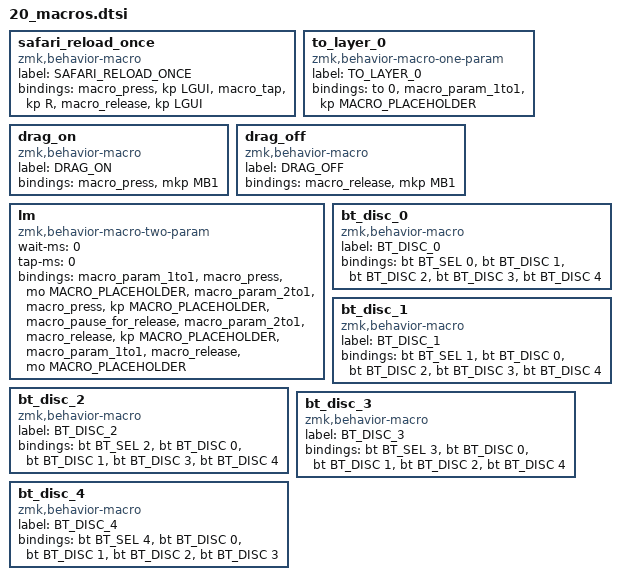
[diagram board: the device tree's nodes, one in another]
/* ============================================================
 * 20_macros.dtsi — マクロ定義
 *
 * macros { } の内側でインクルードされる。
 * ============================================================ */

safari_reload_once: safari_reload_once {
    compatible = "zmk,behavior-macro";
    label = "SAFARI_RELOAD_ONCE";
    #binding-cells = <0>;
    bindings =
        <&macro_press>,
        <&kp LGUI>,
        <&macro_tap>,
        <&kp R>,
        <&macro_release>,
        <&kp LGUI>;
};

to_layer_0: to_layer_0 {
    compatible = "zmk,behavior-macro-one-param";
    label = "TO_LAYER_0";
    #binding-cells = <1>;
    bindings = <&to 0 &macro_param_1to1 &kp MACRO_PLACEHOLDER>;
};

drag_on: drag_on {
    compatible = "zmk,behavior-macro";
    label = "DRAG_ON";
    #binding-cells = <0>;
    bindings = <&macro_press>, <&mkp MB1>;
};

drag_off: drag_off {
    compatible = "zmk,behavior-macro";
    label = "DRAG_OFF";
    #binding-cells = <0>;
    bindings = <&macro_release>, <&mkp MB1>;
};

lm: lm {
    compatible = "zmk,behavior-macro-two-param";
    #binding-cells = <2>;
    wait-ms = <0>;
    tap-ms = <0>;
    bindings =
        <&macro_param_1to1>,
        <&macro_press>,
        <&mo MACRO_PLACEHOLDER &macro_param_2to1>,
        <&macro_press>,
        <&kp MACRO_PLACEHOLDER>,
        <&macro_pause_for_release>,
        <&macro_param_2to1>,
        <&macro_release>,
        <&kp MACRO_PLACEHOLDER &macro_param_1to1>,
        <&macro_release>,
        <&mo MACRO_PLACEHOLDER>;
};

/* ============================================================
 * 〈BT Disc Sigils〉— 複数接続切断 + プロファイル切替
 *
 * bt_disc_N: BT_SEL N で N へ切替後、他 4 profile に BT_DISC を連射し
 * 不要な同時接続を強制切断する。複数ホスト同時接続によるトラックボール遅延
 *（BLE 帯域奪い合い）が起きている時に使用する。
 * 注意: 新規ペアリング中に押すと bond 確立が破壊されるため、
 *       新規ペアリング時は上段の &bt BT_SEL N を使うこと。
 * ============================================================ */

bt_disc_0: bt_disc_0 {
    compatible = "zmk,behavior-macro";
    label = "BT_DISC_0";
    #binding-cells = <0>;
    bindings = <&bt BT_SEL 0>,
               <&bt BT_DISC 1>,
               <&bt BT_DISC 2>,
               <&bt BT_DISC 3>,
               <&bt BT_DISC 4>;
};

bt_disc_1: bt_disc_1 {
    compatible = "zmk,behavior-macro";
    label = "BT_DISC_1";
    #binding-cells = <0>;
    bindings = <&bt BT_SEL 1>,
               <&bt BT_DISC 0>,
               <&bt BT_DISC 2>,
               <&bt BT_DISC 3>,
               <&bt BT_DISC 4>;
};

bt_disc_2: bt_disc_2 {
    compatible = "zmk,behavior-macro";
    label = "BT_DISC_2";
    #binding-cells = <0>;
    bindings = <&bt BT_SEL 2>,
               <&bt BT_DISC 0>,
               <&bt BT_DISC 1>,
               <&bt BT_DISC 3>,
               <&bt BT_DISC 4>;
};

bt_disc_3: bt_disc_3 {
    compatible = "zmk,behavior-macro";
    label = "BT_DISC_3";
    #binding-cells = <0>;
    bindings = <&bt BT_SEL 3>,
               <&bt BT_DISC 0>,
               <&bt BT_DISC 1>,
               <&bt BT_DISC 2>,
               <&bt BT_DISC 4>;
};

bt_disc_4: bt_disc_4 {
    compatible = "zmk,behavior-macro";
    label = "BT_DISC_4";
    #binding-cells = <0>;
    bindings = <&bt BT_SEL 4>,
               <&bt BT_DISC 0>,
               <&bt BT_DISC 1>,
               <&bt BT_DISC 2>,
               <&bt BT_DISC 3>;
};

/* ============================================================
 * 〈Pure Pairing Note〉— 新規ペアリング時は上段の &bt BT_SEL N を使うこと。
 * BT_DISC を発火しないため ペアリング進行中に押しても bond を破壊しない。
 * ============================================================ */
